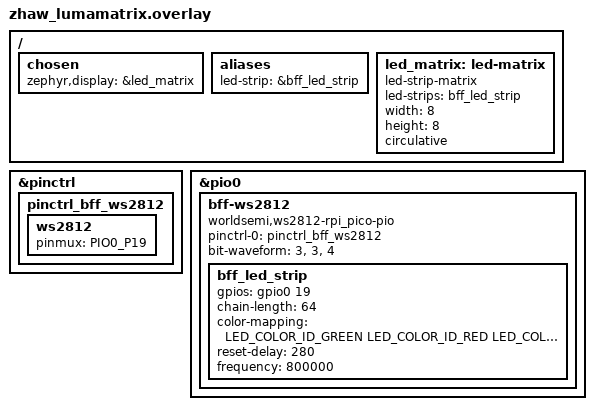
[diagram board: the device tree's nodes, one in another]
#include <zephyr/dt-bindings/led/led.h>

#include <dt-bindings/pinctrl/rpi-pico-rp2040-pinctrl.h>

/ {
	chosen {
		zephyr,display = &led_matrix;
	};

	aliases {
		led-strip = &bff_led_strip;
	};

	led_matrix: led-matrix {
		compatible = "led-strip-matrix";
		status = "okay";
		led-strips = <&bff_led_strip>;
		width = <8>;
		height = <8>;
		circulative;
	};
};

&pinctrl {
	pinctrl_bff_ws2812: pinctrl_bff_ws2812 {
		ws2812 {
			pinmux = <PIO0_P19>;
		};
	};
};

&pio0 {
	status = "okay";

	bff-ws2812 {
		compatible = "worldsemi,ws2812-rpi_pico-pio";
		status = "okay";
		pinctrl-0 = <&pinctrl_bff_ws2812>;
		pinctrl-names = "default";
		bit-waveform = <3>, <3>, <4>;

		bff_led_strip: bff_led_strip {
			status = "okay";
			gpios = <&gpio0 19 GPIO_ACTIVE_HIGH>;
			chain-length = <64>;
			color-mapping = <LED_COLOR_ID_GREEN
					 LED_COLOR_ID_RED
					 LED_COLOR_ID_BLUE>;
			reset-delay = <280>;
			frequency = <800000>;
		};
	};
};

// &buttons {
// 	status = "okay";
// 	compatible = "gpio-keys";

// 	button0: button_0 {
// 		gpios = <&gpio0 3 (GPIO_PULL_UP | GPIO_ACTIVE_LOW)>;
// 		label = "joystick button up";
// 		zephyr,code = <INPUT_KEY_0>;
// 	};

// 	button1: button_1 {
// 		gpios = <&gpio0 6 (GPIO_PULL_UP | GPIO_ACTIVE_LOW)>;
// 		label = "joystick button down";
// 		zephyr,code = <INPUT_KEY_1>;
// 	};

// 	button2: button_2 {
// 		gpios = <&gpio0 7 (GPIO_PULL_UP | GPIO_ACTIVE_LOW)>;
// 		label = "joystick button left";
// 		zephyr,code = <INPUT_KEY_2>;
// 	};

// 	button3: button_3 {
// 		gpios = <&gpio0 2 (GPIO_PULL_UP | GPIO_ACTIVE_LOW)>;
// 		label = "joystick button right";
// 		zephyr,code = <INPUT_KEY_3>;
// 	};

// 	button4: button_4 {
// 		gpios = <&gpio0 8 (GPIO_PULL_UP | GPIO_ACTIVE_LOW)>;
// 		label = "joystick button center";
// 		zephyr,code = <INPUT_KEY_4>;
// 	};

// 	button5: button_5 {
// 		gpios = <&gpio0 9 (GPIO_PULL_UP | GPIO_ACTIVE_LOW)>;
// 		label = "switch";
// 		zephyr,code = <INPUT_KEY_5>;
// 	};
// };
